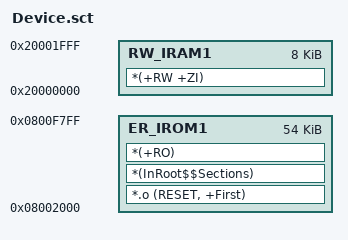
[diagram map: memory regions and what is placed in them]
; *************************************************************
; *** Scatter-Loading Description File generated by uVision ***
; *************************************************************

LR_IROM1 0x8002000 0xd800  {    ; load region size_region
  ER_IROM1 0x8002000 0xd800  {  ; load address = execution address
   *.o (RESET, +First)
   *(InRoot$$Sections)
   *(+RO)
  }
  RW_IRAM1 0x20000000 0x2000  {  ; RW data
   *(+RW +ZI)
  }
}
